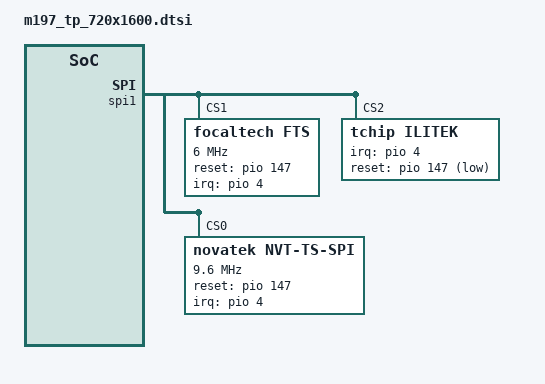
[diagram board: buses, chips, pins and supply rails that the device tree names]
/*
 * Copyright (C) 2024 Novatek, Inc.
 *
 * $Revision$
 * $Date$
 *
 * This program is free software; you can redistribute it and/or modify
 * it under the terms of the GNU General Public License as published by
 * the Free Software Foundation; either version 2 of the License, or
 * (at your option) any later version.
 *
 * This program is distributed in the hope that it will be useful, but WITHOUT
 * ANY WARRANTY; without even the implied warranty of MERCHANTABILITY or
 * FITNESS FOR A PARTICULAR PURPOSE.  See the GNU General Public License for
 * more details.
 *
 */


&spi1 {
	status = "ok";
		#address-cells = <1>;
		#size-cells = <0>;
		pinctrl-names = "default", "ts_int_active",
		"ts_reset_active", "ts_int_suspend",
		"ts_reset_suspend";
		pinctrl-0 = <&ctp_pins_default>;
		pinctrl-1 = <&ctp_ts_int_active>;
		pinctrl-2 = <&ctp_ts_reset_active>;
		pinctrl-3 = <&ctp_ts_int_suspend>;
		pinctrl-4 = <&ctp_ts_reset_suspend>;

    focaltech@1 {
        compatible = "focaltech,fts";
        reg = <1>;
        spi-max-frequency = <6000000>;
        interrupt-parent = <&pio>;
        interrupts = <4 IRQ_TYPE_EDGE_FALLING 4 0>;
        focaltech,reset-gpio = <&pio 147 0>;
        focaltech,irq-gpio = <&pio 4 02>;
        focaltech,max-touch-number = <10>;
        focaltech,display-coords =  <0 0 719 1599>;
        status = "okay";
    };

	ilitek@2{
		status = "ok";
		compatible = "tchip,ilitek";
		reg = <2>;

		touch,irq-gpio = <&pio 4 0x02>;
		touch,reset-gpio = <&pio 147 0x01>;
	};

	/* Novatek device tree node */
	novatek@0 {
		compatible = "novatek,NVT-ts-spi";
		reg = <0>; //Same as CS ID
		status = "ok";

		spi-max-frequency = <9600000>;	//4800000,9600000,15000000,19200000
		novatek,reset-gpio = <&pio 147 0x0>;
		novatek,irq-gpio = <&pio 4 0x0>;

		//novatek,pen-support;
		//novatek,spi-rd-fast-addr = <0x03F310>;

		/* MP */
		novatek,mp-support-dt;

		novatek-mp-criteria-7265@0 {
			#address-cells = <1>;
			#size-cells = <0>;
			compatible = "novatek-mp-criteria-7265";

			/* MP Config */
			IC_X_CFG_SIZE = <18>;
			IC_Y_CFG_SIZE = <32>;
			IC_KEY_CFG_SIZE = <4>;
			X_Channel = <18>;
			Y_Channel = <32>;
			AIN_X = <0 1 2 3 4 5 6 7 8 9 10 11 12 13 14 15 16 17>;
			AIN_Y = <0 1 2 3 4 5 6 7 8 9 10 11 12 13 14 15 16 17 18 19 20 21 22 23 24 25 26 27 28 29 30 31>;
			//AIN_X = <0 1 2 3 4 5 6 7 8 9 10 11 12 13 14 15 16 17 18 19 20 21 22 23 24 25 26 27 28 29 30 31 32 33 34 35 36 37 38 39>;
			//AIN_Y = <0 1 2 3 4 5 6 7 8 9 10 11 12 13 14 15 16 17 18 19 20 21 22 23 24 25 26 27 28 29 30 31 32 33 34 35 36 37 38 39 40 41 42 43 44 45 46 47 48 49 50 51 52 53 54 55 56 57 58 59 60 61 62 63>;
			AIN_KEY = <0 1 2 0xFF>;

			/* MP Criteria */
			PS_Config_Lmt_Short_Rawdata_P = <
				14008 14008 14008 14008 14008 14008 14008 14008 14008 14008 14008 14008 14008 14008 14008 14008 14008 14008
				14008 14008 14008 14008 14008 14008 14008 14008 14008 14008 14008 14008 14008 14008 14008 14008 14008 14008
				14008 14008 14008 14008 14008 14008 14008 14008 14008 14008 14008 14008 14008 14008 14008 14008 14008 14008
				14008 14008 14008 14008 14008 14008 14008 14008 14008 14008 14008 14008 14008 14008 14008 14008 14008 14008
				14008 14008 14008 14008 14008 14008 14008 14008 14008 14008 14008 14008 14008 14008 14008 14008 14008 14008
				14008 14008 14008 14008 14008 14008 14008 14008 14008 14008 14008 14008 14008 14008 14008 14008 14008 14008
				14008 14008 14008 14008 14008 14008 14008 14008 14008 14008 14008 14008 14008 14008 14008 14008 14008 14008
				14008 14008 14008 14008 14008 14008 14008 14008 14008 14008 14008 14008 14008 14008 14008 14008 14008 14008
				14008 14008 14008 14008 14008 14008 14008 14008 14008 14008 14008 14008 14008 14008 14008 14008 14008 14008
				14008 14008 14008 14008 14008 14008 14008 14008 14008 14008 14008 14008 14008 14008 14008 14008 14008 14008
				14008 14008 14008 14008 14008 14008 14008 14008 14008 14008 14008 14008 14008 14008 14008 14008 14008 14008
				14008 14008 14008 14008 14008 14008 14008 14008 14008 14008 14008 14008 14008 14008 14008 14008 14008 14008
				14008 14008 14008 14008 14008 14008 14008 14008 14008 14008 14008 14008 14008 14008 14008 14008 14008 14008
				14008 14008 14008 14008 14008 14008 14008 14008 14008 14008 14008 14008 14008 14008 14008 14008 14008 14008
				14008 14008 14008 14008 14008 14008 14008 14008 14008 14008 14008 14008 14008 14008 14008 14008 14008 14008
				14008 14008 14008 14008 14008 14008 14008 14008 14008 14008 14008 14008 14008 14008 14008 14008 14008 14008
				14008 14008 14008 14008 14008 14008 14008 14008 14008 14008 14008 14008 14008 14008 14008 14008 14008 14008
				14008 14008 14008 14008 14008 14008 14008 14008 14008 14008 14008 14008 14008 14008 14008 14008 14008 14008
				14008 14008 14008 14008 14008 14008 14008 14008 14008 14008 14008 14008 14008 14008 14008 14008 14008 14008
				14008 14008 14008 14008 14008 14008 14008 14008 14008 14008 14008 14008 14008 14008 14008 14008 14008 14008
				14008 14008 14008 14008 14008 14008 14008 14008 14008 14008 14008 14008 14008 14008 14008 14008 14008 14008
				14008 14008 14008 14008 14008 14008 14008 14008 14008 14008 14008 14008 14008 14008 14008 14008 14008 14008
				14008 14008 14008 14008 14008 14008 14008 14008 14008 14008 14008 14008 14008 14008 14008 14008 14008 14008
				14008 14008 14008 14008 14008 14008 14008 14008 14008 14008 14008 14008 14008 14008 14008 14008 14008 14008
				14008 14008 14008 14008 14008 14008 14008 14008 14008 14008 14008 14008 14008 14008 14008 14008 14008 14008
				14008 14008 14008 14008 14008 14008 14008 14008 14008 14008 14008 14008 14008 14008 14008 14008 14008 14008
				14008 14008 14008 14008 14008 14008 14008 14008 14008 14008 14008 14008 14008 14008 14008 14008 14008 14008
				14008 14008 14008 14008 14008 14008 14008 14008 14008 14008 14008 14008 14008 14008 14008 14008 14008 14008
				14008 14008 14008 14008 14008 14008 14008 14008 14008 14008 14008 14008 14008 14008 14008 14008 14008 14008
				14008 14008 14008 14008 14008 14008 14008 14008 14008 14008 14008 14008 14008 14008 14008 14008 14008 14008
				14008 14008 14008 14008 14008 14008 14008 14008 14008 14008 14008 14008 14008 14008 14008 14008 14008 14008
				14008 14008 14008 14008 14008 14008 14008 14008 14008 14008 14008 14008 14008 14008 14008 14008 14008 14008
				14008 14008 14008>;

			PS_Config_Lmt_Short_Rawdata_N = <
				10100 10100 10100 10100 10100 10100 10100 10100 10100 10100 10100 10100 10100 10100 10100 10100 10100 10100
				10100 10100 10100 10100 10100 10100 10100 10100 10100 10100 10100 10100 10100 10100 10100 10100 10100 10100
				10100 10100 10100 10100 10100 10100 10100 10100 10100 10100 10100 10100 10100 10100 10100 10100 10100 10100
				10100 10100 10100 10100 10100 10100 10100 10100 10100 10100 10100 10100 10100 10100 10100 10100 10100 10100
				10100 10100 10100 10100 10100 10100 10100 10100 10100 10100 10100 10100 10100 10100 10100 10100 10100 10100
				10100 10100 10100 10100 10100 10100 10100 10100 10100 10100 10100 10100 10100 10100 10100 10100 10100 10100
				10100 10100 10100 10100 10100 10100 10100 10100 10100 10100 10100 10100 10100 10100 10100 10100 10100 10100
				10100 10100 10100 10100 10100 10100 10100 10100 10100 10100 10100 10100 10100 10100 10100 10100 10100 10100
				10100 10100 10100 10100 10100 10100 10100 10100 10100 10100 10100 10100 10100 10100 10100 10100 10100 10100
				10100 10100 10100 10100 10100 10100 10100 10100 10100 10100 10100 10100 10100 10100 10100 10100 10100 10100
				10100 10100 10100 10100 10100 10100 10100 10100 10100 10100 10100 10100 10100 10100 10100 10100 10100 10100
				10100 10100 10100 10100 10100 10100 10100 10100 10100 10100 10100 10100 10100 10100 10100 10100 10100 10100
				10100 10100 10100 10100 10100 10100 10100 10100 10100 10100 10100 10100 10100 10100 10100 10100 10100 10100
				10100 10100 10100 10100 10100 10100 10100 10100 10100 10100 10100 10100 10100 10100 10100 10100 10100 10100
				10100 10100 10100 10100 10100 10100 10100 10100 10100 10100 10100 10100 10100 10100 10100 10100 10100 10100
				10100 10100 10100 10100 10100 10100 10100 10100 10100 10100 10100 10100 10100 10100 10100 10100 10100 10100
				10100 10100 10100 10100 10100 10100 10100 10100 10100 10100 10100 10100 10100 10100 10100 10100 10100 10100
				10100 10100 10100 10100 10100 10100 10100 10100 10100 10100 10100 10100 10100 10100 10100 10100 10100 10100
				10100 10100 10100 10100 10100 10100 10100 10100 10100 10100 10100 10100 10100 10100 10100 10100 10100 10100
				10100 10100 10100 10100 10100 10100 10100 10100 10100 10100 10100 10100 10100 10100 10100 10100 10100 10100
				10100 10100 10100 10100 10100 10100 10100 10100 10100 10100 10100 10100 10100 10100 10100 10100 10100 10100
				10100 10100 10100 10100 10100 10100 10100 10100 10100 10100 10100 10100 10100 10100 10100 10100 10100 10100
				10100 10100 10100 10100 10100 10100 10100 10100 10100 10100 10100 10100 10100 10100 10100 10100 10100 10100
				10100 10100 10100 10100 10100 10100 10100 10100 10100 10100 10100 10100 10100 10100 10100 10100 10100 10100
				10100 10100 10100 10100 10100 10100 10100 10100 10100 10100 10100 10100 10100 10100 10100 10100 10100 10100
				10100 10100 10100 10100 10100 10100 10100 10100 10100 10100 10100 10100 10100 10100 10100 10100 10100 10100
				10100 10100 10100 10100 10100 10100 10100 10100 10100 10100 10100 10100 10100 10100 10100 10100 10100 10100
				10100 10100 10100 10100 10100 10100 10100 10100 10100 10100 10100 10100 10100 10100 10100 10100 10100 10100
				10100 10100 10100 10100 10100 10100 10100 10100 10100 10100 10100 10100 10100 10100 10100 10100 10100 10100
				10100 10100 10100 10100 10100 10100 10100 10100 10100 10100 10100 10100 10100 10100 10100 10100 10100 10100
				10100 10100 10100 10100 10100 10100 10100 10100 10100 10100 10100 10100 10100 10100 10100 10100 10100 10100
				10100 10100 10100 10100 10100 10100 10100 10100 10100 10100 10100 10100 10100 10100 10100 10100 10100 10100
				10000 10000 10000>;

			PS_Config_Lmt_Open_Rawdata_P = <
				2852 2874 2804 2751 2661 2573 2521 2442 2442 2419 2419 2481 2528 2596 2657 2691 2752 2780
				2971 3007 2968 2920 2856 2794 2751 2708 2675 2570 2591 2624 2663 2702 2736 2768 2799 2829
				3003 3035 3003 2955 2895 2834 2783 2737 2710 2598 2611 2646 2681 2723 2759 2786 2817 2852
				2944 3000 2965 2915 2852 2789 2738 2691 2664 2632 2650 2680 2716 2752 2787 2818 2849 2883
				3042 3098 3058 3004 2941 2878 2825 2782 2752 2667 2681 2717 2754 2799 2832 2859 2890 2918
				3069 3144 3104 3052 2988 2922 2867 2821 2797 2702 2716 2754 2792 2832 2870 2899 2937 2962
				2971 2962 2951 2916 2850 2783 2748 2694 2661 2758 2780 2821 2846 2892 2939 2957 2983 2883
				2986 2971 2953 2918 2855 2790 2754 2706 2670 2779 2808 2848 2878 2927 2971 2995 3009 2922
				3080 3065 3039 3002 2937 2873 2835 2786 2747 2818 2836 2878 2905 2958 3003 3023 3045 2976
				3109 3086 3066 3025 2961 2897 2857 2803 2765 2843 2863 2905 2923 2968 3011 3039 3059 2996
				3129 3107 3080 3046 2982 2923 2888 2841 2803 2939 2967 3003 3038 3087 3132 3156 3182 3123
				3191 3165 3140 3101 3034 2971 2932 2876 2845 2941 2962 3006 3041 3091 3137 3164 3188 3142
				3223 3200 3188 3151 3080 3009 2974 2918 2888 2918 2946 2983 3017 3065 3102 3123 3147 3122
				3304 3276 3238 3202 3135 3069 3025 2972 2937 2997 3018 3058 3093 3142 3178 3200 3224 3198
				3336 3310 3270 3235 3171 3107 3063 3014 2985 3069 3094 3140 3171 3223 3265 3283 3318 3310
				3401 3377 3347 3304 3234 3167 3122 3073 3044 3037 3062 3105 3137 3188 3231 3258 3291 3296
				3464 3434 3405 3361 3294 3226 3179 3122 3086 3133 3151 3198 3235 3287 3331 3354 3391 3406
				3520 3486 3455 3410 3342 3276 3235 3175 3144 3116 3136 3185 3214 3263 3310 3338 3370 3391
				3541 3511 3472 3431 3354 3290 3252 3189 3160 3199 3223 3266 3307 3356 3401 3427 3450 3465
				3571 3541 3504 3462 3392 3331 3289 3234 3198 3217 3248 3290 3331 3374 3420 3445 3473 3506
				3683 3651 3611 3567 3494 3423 3380 3326 3287 3245 3279 3328 3360 3408 3459 3482 3520 3553
				3730 3703 3665 3616 3546 3475 3429 3375 3339 3380 3409 3445 3479 3527 3571 3599 3634 3664
				3765 3731 3695 3648 3585 3524 3479 3431 3387 3408 3440 3485 3528 3574 3622 3647 3678 3713
				3823 3791 3758 3709 3641 3576 3525 3471 3429 3387 3415 3458 3499 3548 3595 3627 3667 3692
				3954 3917 3884 3835 3758 3688 3643 3588 3541 3497 3531 3576 3616 3664 3711 3741 3777 3805
				3882 3857 3823 3769 3695 3625 3574 3518 3476 3542 3571 3619 3657 3704 3753 3786 3822 3853
				3815 3977 3933 3878 3809 3739 3695 3641 3605 3555 3588 3632 3671 3717 3765 3804 3843 3697
				3854 4025 3986 3938 3863 3798 3748 3688 3650 3623 3654 3703 3746 3791 3844 3874 3914 3756
				3905 4099 4063 4018 3938 3867 3811 3752 3707 3674 3703 3746 3787 3840 3891 3917 3956 3788
				3956 4171 4137 4078 4003 3930 3878 3822 3786 3686 3718 3770 3814 3861 3909 3945 3979 3801
				4021 4264 4221 4168 4095 4021 3966 3909 3863 3756 3791 3837 3882 3937 3987 4026 4071 3881
				4276 4280 4301 4248 4166 4091 4031 3962 3903 3849 3888 3937 3980 4031 4074 4113 4087 4130
				5120 5120 5120>;

			PS_Config_Lmt_Open_Rawdata_N = <
				1222 1232 1202 1179 1141 1103 1081 1046 1046 1037 1037 1063 1084 1112 1139 1153 1180 1192
				1273 1289 1272 1252 1224 1198 1179 1160 1147 1102 1111 1124 1141 1158 1172 1186 1199 1213
				1287 1301 1287 1267 1241 1214 1193 1173 1162 1114 1119 1134 1149 1167 1183 1194 1207 1222
				1262 1286 1271 1249 1222 1195 1174 1153 1142 1128 1136 1148 1164 1180 1195 1208 1221 1235
				1304 1328 1310 1288 1261 1234 1211 1192 1180 1143 1149 1165 1180 1199 1214 1225 1238 1250
				1315 1348 1330 1308 1280 1252 1229 1209 1199 1158 1164 1180 1196 1214 1230 1243 1259 1270
				1273 1270 1265 1250 1222 1193 1178 1154 1141 1182 1192 1209 1220 1240 1259 1267 1279 1235
				1280 1273 1265 1250 1223 1196 1180 1160 1144 1191 1204 1220 1234 1255 1273 1283 1289 1252
				1320 1313 1303 1286 1259 1231 1215 1194 1177 1208 1216 1234 1245 1268 1287 1295 1305 1276
				1333 1322 1314 1297 1269 1241 1225 1201 1185 1219 1227 1245 1253 1272 1291 1303 1311 1284
				1341 1331 1320 1306 1278 1253 1238 1217 1201 1259 1271 1287 1302 1323 1342 1352 1364 1339
				1367 1357 1346 1329 1300 1273 1256 1232 1219 1261 1270 1288 1303 1325 1345 1356 1366 1346
				1381 1372 1366 1351 1320 1289 1274 1250 1238 1250 1262 1279 1293 1313 1330 1339 1349 1338
				1416 1404 1388 1372 1343 1315 1297 1274 1259 1285 1294 1310 1325 1346 1362 1372 1382 1370
				1430 1418 1402 1387 1359 1331 1313 1292 1279 1315 1326 1346 1359 1381 1399 1407 1422 1418
				1457 1447 1435 1416 1386 1357 1338 1317 1304 1301 1312 1331 1345 1366 1385 1396 1411 1412
				1484 1472 1459 1441 1412 1382 1363 1338 1322 1343 1351 1370 1387 1409 1427 1438 1453 1460
				1508 1494 1481 1462 1432 1404 1387 1361 1348 1336 1344 1365 1378 1399 1418 1430 1444 1453
				1517 1505 1488 1471 1438 1410 1394 1367 1354 1371 1381 1400 1417 1438 1457 1469 1478 1485
				1531 1517 1502 1484 1454 1427 1409 1386 1370 1379 1392 1410 1427 1446 1466 1477 1489 1502
				1579 1565 1547 1529 1498 1467 1448 1426 1409 1391 1405 1426 1440 1460 1483 1492 1508 1523
				1598 1587 1571 1550 1520 1489 1469 1447 1431 1448 1461 1477 1491 1511 1531 1543 1558 1570
				1613 1599 1583 1564 1537 1510 1491 1471 1451 1460 1474 1493 1512 1532 1552 1563 1576 1591
				1639 1625 1610 1589 1561 1532 1511 1487 1469 1451 1463 1482 1499 1520 1541 1555 1571 1582
				1694 1679 1664 1643 1610 1580 1561 1538 1517 1499 1513 1532 1550 1570 1591 1603 1619 1631
				1664 1653 1639 1615 1583 1553 1532 1508 1490 1518 1531 1551 1567 1588 1609 1622 1638 1651
				1635 1705 1685 1662 1633 1603 1583 1561 1545 1523 1538 1556 1573 1593 1613 1630 1647 1585
				1652 1725 1708 1688 1655 1628 1606 1580 1564 1553 1566 1587 1606 1625 1648 1660 1678 1610
				1673 1757 1741 1722 1688 1657 1633 1608 1589 1574 1587 1606 1623 1646 1667 1679 1696 1624
				1696 1787 1773 1748 1715 1684 1662 1638 1622 1580 1594 1616 1634 1655 1675 1691 1705 1629
				1723 1828 1809 1786 1755 1723 1700 1675 1655 1610 1625 1645 1664 1687 1709 1726 1745 1663
				1832 1834 1843 1820 1786 1753 1727 1698 1673 1649 1666 1687 1706 1727 1746 1763 1751 1770
				(-511) (-511) (-511)>;

			PS_Config_Lmt_FW_Rawdata_P = <
				1119 1137 1096 1116 1100 1126 1140 1131 1131 1147 1147 1120 1105 1124 1131 1110 1075 1116
				1114 1137 1093 1121 1113 1103 1093 1107 1113 1075 1151 1165 1124 1093 1071 1133 1095 1158
				1124 1138 1106 1121 1114 1113 1117 1096 1141 1142 1082 1089 1112 1121 1120 1086 1113 1112
				1165 1081 1058 1112 1092 1084 1064 1065 1140 1126 1123 1130 1145 1144 1112 1124 1134 1117
				1140 1114 1137 1127 1130 1135 1121 1128 1131 1131 1105 1093 1084 1085 1110 1144 1093 1119
				1175 1112 1093 1138 1126 1126 1107 1092 1141 1105 1126 1141 1137 1113 1114 1144 1131 1135
				1098 1103 1107 1140 1161 1140 1138 1144 1138 1128 1144 1140 1140 1148 1131 1103 1100 1176
				1127 1112 1152 1126 1117 1093 1103 1107 1130 1114 1148 1145 1128 1145 1159 1078 1099 1149
				1092 1102 1107 1107 1116 1138 1119 1120 1095 1102 1135 1128 1140 1144 1127 1124 1124 1099
				1145 1109 1112 1134 1149 1156 1147 1107 1109 1130 1138 1133 1127 1133 1131 1113 1144 1093
				1135 1131 1120 1144 1141 1137 1147 1149 1135 1121 1147 1137 1133 1124 1124 1105 1134 1098
				1100 1140 1103 1093 1081 1081 1095 1105 1142 1109 1102 1110 1112 1113 1100 1084 1135 1113
				1096 1130 1105 1089 1088 1091 1102 1106 1133 1127 1103 1100 1116 1113 1113 1086 1127 1099
				1109 1114 1124 1134 1140 1137 1142 1138 1096 1124 1093 1092 1078 1078 1092 1082 1119 1112
				1119 1096 1148 1162 1163 1155 1149 1106 1082 1106 1142 1135 1134 1135 1140 1141 1130 1120
				1107 1126 1086 1093 1098 1089 1084 1091 1135 1124 1135 1133 1124 1117 1123 1107 1141 1127
				1116 1126 1128 1142 1145 1138 1145 1144 1112 1106 1152 1152 1147 1148 1141 1121 1130 1128
				1096 1105 1156 1138 1142 1154 1155 1148 1093 1110 1141 1128 1120 1124 1155 1144 1114 1095
				1130 1072 1156 1173 1173 1159 1147 1152 1095 1103 1117 1116 1123 1134 1135 1145 1103 1117
				1138 1109 1148 1138 1135 1148 1144 1142 1096 1116 1138 1135 1142 1137 1134 1128 1089 1134
				1131 1127 1089 1098 1095 1095 1095 1100 1130 1133 1092 1100 1096 1092 1092 1120 1128 1107
				1154 1140 1123 1154 1152 1149 1152 1149 1110 1135 1135 1127 1140 1134 1138 1119 1142 1141
				1127 1103 1124 1131 1137 1148 1152 1151 1096 1154 1130 1141 1137 1130 1121 1098 1151 1155
				1105 1106 1141 1116 1110 1109 1100 1102 1096 1114 1102 1110 1120 1117 1114 1116 1123 1096
				1156 1135 1127 1134 1140 1137 1135 1133 1131 1119 1120 1120 1130 1127 1126 1131 1149 1130
				1121 1126 1121 1127 1106 1103 1105 1100 1127 1100 1142 1145 1148 1148 1151 1138 1116 1145
				1107 1163 1124 1152 1133 1128 1116 1123 1116 1089 1163 1165 1155 1162 1163 1159 1084 1103
				1127 1119 1123 1078 1072 1064 1063 1064 1121 1110 1126 1130 1134 1140 1133 1142 1121 1086
				1074 1137 1127 1134 1140 1135 1127 1123 1098 1123 1130 1127 1126 1128 1147 1123 1141 1126
				1152 1152 1113 1130 1133 1133 1128 1131 1109 1126 1116 1121 1121 1126 1126 1131 1147 1151
				1127 1127 1141 1112 1134 1135 1124 1137 1109 1109 1144 1141 1119 1110 1138 1103 1135 1093
				1114 1141 1141 1148 1135 1145 1141 1140 1092 1098 1155 1163 1154 1159 1130 1144 1088 1102
				3840 3840 3840>;

			PS_Config_Lmt_FW_Rawdata_N = <
				479 487 470 478 472 482 488 485 485 491 491 480 473 482 485 476 461 478
				478 487 469 481 477 473 469 475 477 461 493 499 482 469 459 485 469 496
				482 488 474 481 478 477 479 470 489 490 464 467 476 481 480 466 477 476
				499 463 454 476 468 464 456 457 488 482 481 484 491 490 476 482 486 479
				488 478 487 483 484 487 481 484 485 485 473 469 464 465 476 490 469 479
				503 476 469 488 482 482 475 468 489 473 482 489 487 477 478 490 485 487
				470 473 475 488 497 488 488 490 488 484 490 488 488 492 485 473 472 504
				483 476 494 482 479 469 473 475 484 478 492 491 484 491 497 462 471 493
				468 472 475 475 478 488 479 480 469 472 487 484 488 490 483 482 482 471
				491 475 476 486 493 496 491 475 475 484 488 485 483 485 485 477 490 469
				487 485 480 490 489 487 491 493 487 481 491 487 485 482 482 473 486 470
				472 488 473 469 463 463 469 473 490 475 472 476 476 477 472 464 487 477
				470 484 473 467 466 467 472 474 485 483 473 472 478 477 477 466 483 471
				475 478 482 486 488 487 490 488 470 482 469 468 462 462 468 464 479 476
				479 470 492 498 499 495 493 474 464 474 490 487 486 487 488 489 484 480
				475 482 466 469 470 467 464 467 487 482 487 485 482 479 481 475 489 483
				478 482 484 490 491 488 491 490 476 474 494 494 491 492 489 481 484 484
				470 473 496 488 490 494 495 492 469 476 489 484 480 482 495 490 478 469
				484 460 496 503 503 497 491 494 469 473 479 478 481 486 487 491 473 479
				488 475 492 488 487 492 490 490 470 478 488 487 490 487 486 484 467 486
				485 483 467 470 469 469 469 472 484 485 468 472 470 468 468 480 484 475
				494 488 481 494 494 493 494 493 476 487 487 483 488 486 488 479 490 489
				483 473 482 485 487 492 494 493 470 494 484 489 487 484 481 470 493 495
				473 474 489 478 476 475 472 472 470 478 472 476 480 479 478 478 481 470
				496 487 483 486 488 487 487 485 485 479 480 480 484 483 482 485 493 484
				481 482 481 483 474 473 473 472 483 472 490 491 492 492 493 488 478 491
				475 499 482 494 485 484 478 481 478 467 499 499 495 498 499 497 464 473
				483 479 481 462 460 456 455 456 481 476 482 484 486 488 485 490 481 466
				460 487 483 486 488 487 483 481 470 481 484 483 482 484 491 481 489 482
				494 494 477 484 485 485 484 485 475 482 478 481 481 482 482 485 491 493
				483 483 489 476 486 487 482 487 475 475 490 489 479 476 488 473 487 469
				478 489 489 492 487 491 489 488 468 470 495 499 494 497 484 490 466 472
				240 240 240>;

			PS_Config_Lmt_FW_CC_P = <
				48 46 43 43 41 41 41 41 41 40 40 41 41 41 41 43 46 48
				51 48 47 46 46 46 46 46 46 46 44 44 46 46 46 46 48 50
				51 48 47 46 46 46 46 46 46 46 46 46 46 46 46 47 48 51
				50 48 47 46 46 46 46 46 46 46 46 46 46 46 46 47 48 51
				51 50 47 47 47 47 46 46 47 47 46 46 46 46 46 47 48 51
				51 50 47 47 47 46 46 46 47 47 46 46 46 46 46 47 48 51
				51 50 48 46 46 46 46 46 46 46 46 46 46 46 46 48 50 51
				51 50 47 46 46 46 46 46 46 46 46 46 46 46 46 48 50 51
				52 50 48 47 47 46 47 47 47 47 46 46 46 46 46 48 50 51
				52 50 48 46 46 46 46 46 47 47 46 46 46 46 46 48 50 51
				52 50 48 46 46 46 46 46 47 47 47 47 47 47 47 48 50 52
				52 50 48 47 47 47 47 47 47 47 47 47 46 46 46 48 50 52
				52 50 48 47 47 47 47 47 47 47 47 47 47 47 47 48 50 52
				52 50 48 47 46 46 47 47 47 47 47 47 47 47 47 48 50 52
				52 50 48 47 47 47 47 47 47 47 47 47 47 47 47 48 50 52
				52 50 48 47 47 47 47 47 47 47 47 47 47 47 47 48 50 52
				52 50 48 47 47 47 47 47 47 48 47 47 47 47 47 48 50 52
				52 50 48 47 47 47 47 47 47 47 47 47 47 47 47 48 50 52
				52 51 48 47 47 47 47 47 48 48 47 47 47 47 47 48 51 52
				54 51 48 47 47 47 47 47 48 47 47 47 47 47 47 48 50 52
				54 51 48 47 48 48 48 47 48 48 47 47 47 47 47 48 50 52
				52 51 48 47 47 47 47 47 48 48 47 47 47 47 47 48 50 52
				54 51 50 48 48 48 48 48 48 48 47 47 47 47 47 48 51 54
				54 51 50 48 48 48 48 48 48 48 48 48 48 48 48 48 51 54
				54 51 50 48 48 48 48 48 48 48 48 48 48 48 48 50 51 54
				54 51 50 48 48 48 48 48 48 48 47 47 47 47 48 48 51 54
				54 51 50 48 48 48 48 48 50 48 48 48 48 48 48 50 51 52
				52 51 50 48 48 48 48 48 48 50 48 48 48 48 48 50 52 54
				54 52 50 48 48 48 48 48 50 48 48 48 48 48 48 50 51 52
				52 51 50 48 48 48 48 48 50 48 48 48 48 48 48 50 51 52
				52 51 50 48 48 48 48 48 48 48 47 48 48 48 48 50 51 52
				54 51 50 48 48 48 48 48 48 48 48 48 48 48 48 50 51 54
				314 314 314>;

			PS_Config_Lmt_FW_CC_N = <
				22 20 19 19 19 19 19 19 19 18 18 19 19 19 19 19 20 22
				23 22 21 20 20 20 20 20 20 20 20 20 20 20 20 20 22 22
				23 22 21 20 20 20 20 20 20 20 20 20 20 20 20 21 22 23
				22 22 21 20 20 20 20 20 20 20 20 20 20 20 20 21 22 23
				23 22 21 21 21 21 20 20 21 21 20 20 20 20 20 21 22 23
				23 22 21 21 21 20 20 20 21 21 20 20 20 20 20 21 22 23
				23 22 22 20 20 20 20 20 20 20 20 20 20 20 20 22 22 23
				23 22 21 20 20 20 20 20 20 20 20 20 20 20 20 22 22 23
				24 22 22 21 21 20 21 21 21 21 20 20 20 20 20 22 22 23
				24 22 22 20 20 20 20 20 21 21 20 20 20 20 20 22 22 23
				24 22 22 20 20 20 20 20 21 21 21 21 21 21 21 22 22 24
				24 22 22 21 21 21 21 21 21 21 21 21 20 20 20 22 22 24
				24 22 22 21 21 21 21 21 21 21 21 21 21 21 21 22 22 24
				24 22 22 21 20 20 21 21 21 21 21 21 21 21 21 22 22 24
				24 22 22 21 21 21 21 21 21 21 21 21 21 21 21 22 22 24
				24 22 22 21 21 21 21 21 21 21 21 21 21 21 21 22 22 24
				24 22 22 21 21 21 21 21 21 22 21 21 21 21 21 22 22 24
				24 22 22 21 21 21 21 21 21 21 21 21 21 21 21 22 22 24
				24 23 22 21 21 21 21 21 22 22 21 21 21 21 21 22 23 24
				24 23 22 21 21 21 21 21 22 21 21 21 21 21 21 22 22 24
				24 23 22 21 22 22 22 21 22 22 21 21 21 21 21 22 22 24
				24 23 22 21 21 21 21 21 22 22 21 21 21 21 21 22 22 24
				24 23 22 22 22 22 22 22 22 22 21 21 21 21 21 22 23 24
				24 23 22 22 22 22 22 22 22 22 22 22 22 22 22 22 23 24
				24 23 22 22 22 22 22 22 22 22 22 22 22 22 22 22 23 24
				24 23 22 22 22 22 22 22 22 22 21 21 21 21 22 22 23 24
				24 23 22 22 22 22 22 22 22 22 22 22 22 22 22 22 23 24
				24 23 22 22 22 22 22 22 22 22 22 22 22 22 22 22 24 24
				24 24 22 22 22 22 22 22 22 22 22 22 22 22 22 22 23 24
				24 23 22 22 22 22 22 22 22 22 22 22 22 22 22 22 23 24
				24 23 22 22 22 22 22 22 22 22 21 22 22 22 22 22 23 24
				24 23 22 22 22 22 22 22 22 22 22 22 22 22 22 22 23 24
				0 0 0>;

			PS_Config_Lmt_FW_Diff_P = <
				50 50 50 50 50 50 50 50 50 50 50 50 50 50 50 50 50 50
				50 50 50 50 50 50 50 50 50 50 50 50 50 50 50 50 50 50
				50 50 50 50 50 50 50 50 50 50 50 50 50 50 50 50 50 50
				50 50 50 50 50 50 50 50 50 50 50 50 50 50 50 50 50 50
				50 50 50 50 50 50 50 50 50 50 50 50 50 50 50 50 50 50
				50 50 50 50 50 50 50 50 50 50 50 50 50 50 50 50 50 50
				50 50 50 50 50 50 50 50 50 50 50 50 50 50 50 50 50 50
				50 50 50 50 50 50 50 50 50 50 50 50 50 50 50 50 50 50
				50 50 50 50 50 50 50 50 50 50 50 50 50 50 50 50 50 50
				50 50 50 50 50 50 50 50 50 50 50 50 50 50 50 50 50 50
				50 50 50 50 50 50 50 50 50 50 50 50 50 50 50 50 50 50
				50 50 50 50 50 50 50 50 50 50 50 50 50 50 50 50 50 50
				50 50 50 50 50 50 50 50 50 50 50 50 50 50 50 50 50 50
				50 50 50 50 50 50 50 50 50 50 50 50 50 50 50 50 50 50
				50 50 50 50 50 50 50 50 50 50 50 50 50 50 50 50 50 50
				50 50 50 50 50 50 50 50 50 50 50 50 50 50 50 50 50 50
				50 50 50 50 50 50 50 50 50 50 50 50 50 50 50 50 50 50
				50 50 50 50 50 50 50 50 50 50 50 50 50 50 50 50 50 50
				50 50 50 50 50 50 50 50 50 50 50 50 50 50 50 50 50 50
				50 50 50 50 50 50 50 50 50 50 50 50 50 50 50 50 50 50
				50 50 50 50 50 50 50 50 50 50 50 50 50 50 50 50 50 50
				50 50 50 50 50 50 50 50 50 50 50 50 50 50 50 50 50 50
				50 50 50 50 50 50 50 50 50 50 50 50 50 50 50 50 50 50
				50 50 50 50 50 50 50 50 50 50 50 50 50 50 50 50 50 50
				50 50 50 50 50 50 50 50 50 50 50 50 50 50 50 50 50 50
				50 50 50 50 50 50 50 50 50 50 50 50 50 50 50 50 50 50
				50 50 50 50 50 50 50 50 50 50 50 50 50 50 50 50 50 50
				50 50 50 50 50 50 50 50 50 50 50 50 50 50 50 50 50 50
				50 50 50 50 50 50 50 50 50 50 50 50 50 50 50 50 50 50
				50 50 50 50 50 50 50 50 50 50 50 50 50 50 50 50 50 50
				50 50 50 50 50 50 50 50 50 50 50 50 50 50 50 50 50 50
				50 50 50 50 50 50 50 50 50 50 50 50 50 50 50 50 50 50
				75 75 75>;

			PS_Config_Lmt_FW_Diff_N = <
				(-50) (-50) (-50) (-50) (-50) (-50) (-50) (-50) (-50) (-50) (-50) (-50) (-50) (-50) (-50) (-50) (-50) (-50)
				(-50) (-50) (-50) (-50) (-50) (-50) (-50) (-50) (-50) (-50) (-50) (-50) (-50) (-50) (-50) (-50) (-50) (-50)
				(-50) (-50) (-50) (-50) (-50) (-50) (-50) (-50) (-50) (-50) (-50) (-50) (-50) (-50) (-50) (-50) (-50) (-50)
				(-50) (-50) (-50) (-50) (-50) (-50) (-50) (-50) (-50) (-50) (-50) (-50) (-50) (-50) (-50) (-50) (-50) (-50)
				(-50) (-50) (-50) (-50) (-50) (-50) (-50) (-50) (-50) (-50) (-50) (-50) (-50) (-50) (-50) (-50) (-50) (-50)
				(-50) (-50) (-50) (-50) (-50) (-50) (-50) (-50) (-50) (-50) (-50) (-50) (-50) (-50) (-50) (-50) (-50) (-50)
				(-50) (-50) (-50) (-50) (-50) (-50) (-50) (-50) (-50) (-50) (-50) (-50) (-50) (-50) (-50) (-50) (-50) (-50)
				(-50) (-50) (-50) (-50) (-50) (-50) (-50) (-50) (-50) (-50) (-50) (-50) (-50) (-50) (-50) (-50) (-50) (-50)
				(-50) (-50) (-50) (-50) (-50) (-50) (-50) (-50) (-50) (-50) (-50) (-50) (-50) (-50) (-50) (-50) (-50) (-50)
				(-50) (-50) (-50) (-50) (-50) (-50) (-50) (-50) (-50) (-50) (-50) (-50) (-50) (-50) (-50) (-50) (-50) (-50)
				(-50) (-50) (-50) (-50) (-50) (-50) (-50) (-50) (-50) (-50) (-50) (-50) (-50) (-50) (-50) (-50) (-50) (-50)
				(-50) (-50) (-50) (-50) (-50) (-50) (-50) (-50) (-50) (-50) (-50) (-50) (-50) (-50) (-50) (-50) (-50) (-50)
				(-50) (-50) (-50) (-50) (-50) (-50) (-50) (-50) (-50) (-50) (-50) (-50) (-50) (-50) (-50) (-50) (-50) (-50)
				(-50) (-50) (-50) (-50) (-50) (-50) (-50) (-50) (-50) (-50) (-50) (-50) (-50) (-50) (-50) (-50) (-50) (-50)
				(-50) (-50) (-50) (-50) (-50) (-50) (-50) (-50) (-50) (-50) (-50) (-50) (-50) (-50) (-50) (-50) (-50) (-50)
				(-50) (-50) (-50) (-50) (-50) (-50) (-50) (-50) (-50) (-50) (-50) (-50) (-50) (-50) (-50) (-50) (-50) (-50)
				(-50) (-50) (-50) (-50) (-50) (-50) (-50) (-50) (-50) (-50) (-50) (-50) (-50) (-50) (-50) (-50) (-50) (-50)
				(-50) (-50) (-50) (-50) (-50) (-50) (-50) (-50) (-50) (-50) (-50) (-50) (-50) (-50) (-50) (-50) (-50) (-50)
				(-50) (-50) (-50) (-50) (-50) (-50) (-50) (-50) (-50) (-50) (-50) (-50) (-50) (-50) (-50) (-50) (-50) (-50)
				(-50) (-50) (-50) (-50) (-50) (-50) (-50) (-50) (-50) (-50) (-50) (-50) (-50) (-50) (-50) (-50) (-50) (-50)
				(-50) (-50) (-50) (-50) (-50) (-50) (-50) (-50) (-50) (-50) (-50) (-50) (-50) (-50) (-50) (-50) (-50) (-50)
				(-50) (-50) (-50) (-50) (-50) (-50) (-50) (-50) (-50) (-50) (-50) (-50) (-50) (-50) (-50) (-50) (-50) (-50)
				(-50) (-50) (-50) (-50) (-50) (-50) (-50) (-50) (-50) (-50) (-50) (-50) (-50) (-50) (-50) (-50) (-50) (-50)
				(-50) (-50) (-50) (-50) (-50) (-50) (-50) (-50) (-50) (-50) (-50) (-50) (-50) (-50) (-50) (-50) (-50) (-50)
				(-50) (-50) (-50) (-50) (-50) (-50) (-50) (-50) (-50) (-50) (-50) (-50) (-50) (-50) (-50) (-50) (-50) (-50)
				(-50) (-50) (-50) (-50) (-50) (-50) (-50) (-50) (-50) (-50) (-50) (-50) (-50) (-50) (-50) (-50) (-50) (-50)
				(-50) (-50) (-50) (-50) (-50) (-50) (-50) (-50) (-50) (-50) (-50) (-50) (-50) (-50) (-50) (-50) (-50) (-50)
				(-50) (-50) (-50) (-50) (-50) (-50) (-50) (-50) (-50) (-50) (-50) (-50) (-50) (-50) (-50) (-50) (-50) (-50)
				(-50) (-50) (-50) (-50) (-50) (-50) (-50) (-50) (-50) (-50) (-50) (-50) (-50) (-50) (-50) (-50) (-50) (-50)
				(-50) (-50) (-50) (-50) (-50) (-50) (-50) (-50) (-50) (-50) (-50) (-50) (-50) (-50) (-50) (-50) (-50) (-50)
				(-50) (-50) (-50) (-50) (-50) (-50) (-50) (-50) (-50) (-50) (-50) (-50) (-50) (-50) (-50) (-50) (-50) (-50)
				(-50) (-50) (-50) (-50) (-50) (-50) (-50) (-50) (-50) (-50) (-50) (-50) (-50) (-50) (-50) (-50) (-50) (-50)
				(-75) (-75) (-75)>;

			PS_Config_Diff_Test_Frame = <50>;
		};
	};
};

&pio {
	ctp_pins_default: eintdefault {
	};
	ctp_ts_int_active: int-active {
		pins-cmd-dat {
			pinmux = <PINMUX_GPIO4__FUNC_GPIO4>;
			input-enable;
		};
	};
	ctp_ts_reset_active: reset-active {
		pins-cmd-dat {
			pinmux = <PINMUX_GPIO147__FUNC_GPIO147>;
			output-high;
		};
	};
	ctp_ts_int_suspend: int-suspend {
		pins-cmd-dat {
			pinmux = <PINMUX_GPIO4__FUNC_GPIO4>;
			output-low;
		};
	};
	ctp_ts_reset_suspend: reset-suspend {
		pins-cmd-dat {
			pinmux = <PINMUX_GPIO147__FUNC_GPIO147>;
			output-low;
		};
	};
};

